# COMPUTE_CLUSTER0_A72SS0_COMMON_ECC_AGGR_MPU0_COREPAC_ECC_AGGR register map
Vendor: Texas Instruments
Peripheral module from a debugger description file (folder J721S2).
Registers are 32-bit, access not given, reset 0x0 unless marked. A register's access mark holds for its fields unless they carry their own. Offsets are as the file gives them; lines under a group give offsets from that group; [hi:lo] are bit positions; {n}, {i} and the like mark numbered series; 'fields as' and 'values as' point back to an identical list; <NAME> marks a mode.

## COMPUTE_CLUSTER0_A72SS0_COMMON_ECC_AGGR_MPU0_COREPAC_ECC_AGGR
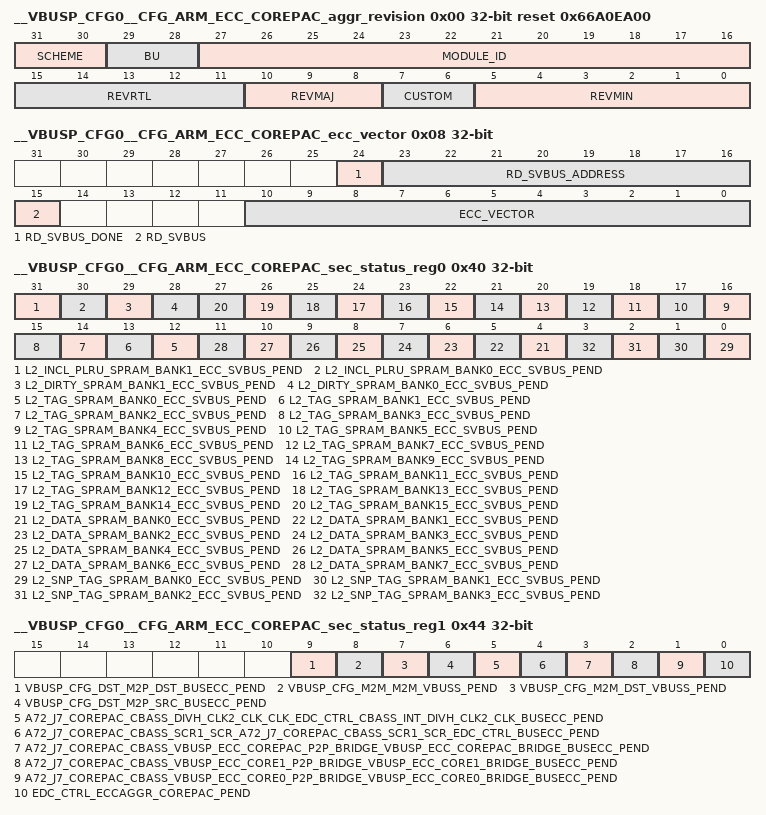
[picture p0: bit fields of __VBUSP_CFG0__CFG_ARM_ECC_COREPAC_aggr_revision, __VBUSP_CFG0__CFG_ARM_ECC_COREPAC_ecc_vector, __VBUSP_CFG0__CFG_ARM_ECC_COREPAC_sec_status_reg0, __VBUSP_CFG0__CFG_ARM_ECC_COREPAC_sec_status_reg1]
0x00 __VBUSP_CFG0__CFG_ARM_ECC_COREPAC_aggr_revision ro reset 0x66A0EA00 — Revision parameters
  [31:30] SCHEME
  [29:28] BU
  [27:16] MODULE_ID
  [15:11] REVRTL — RTL version
  [10:8] REVMAJ — Major version
  [7:6] CUSTOM — Custom version
  [5:0] REVMIN — Minor version
0x08 __VBUSP_CFG0__CFG_ARM_ECC_COREPAC_ecc_vector — ECC Vector Register
  [24] RD_SVBUS_DONE — Status to indicate if read on serial VBUS is complete, write of any value will clear this bit. (access R/W1TC)
  [23:16] RD_SVBUS_ADDRESS rw — Read address
  [15] RD_SVBUS — Write 1 to trigger a read on the serial VBUS (access R/W1TS)
  [10:0] ECC_VECTOR rw — Value written to select the corresponding ECC RAM for control or status
0x0C __VBUSP_CFG0__CFG_ARM_ECC_COREPAC_misc_status ro reset 0x2A — Misc Status
  [10:0] NUM_RAMS — Indicates the number of RAMS serviced by the ECC aggregator
0x10 __VBUSP_CFG0__CFG_ARM_ECC_COREPAC_reserved_svbus rw — Reference other documents that contain the ECC RAM wrapper and EDC controller serial vbus register sets.
  [31:0] DATA — Serial VBUS register data
0x3C __VBUSP_CFG0__CFG_ARM_ECC_COREPAC_sec_eoi_reg — EOI Register
  [0] EOI_WR — EOI Register (access R/W1TS)
0x40 __VBUSP_CFG0__CFG_ARM_ECC_COREPAC_sec_status_reg0 — Interrupt Status Register 0
  [31] L2_INCL_PLRU_SPRAM_BANK1_ECC_SVBUS_PEND — Interrupt Pending Status for l2_incl_plru_spram_bank1_ecc_svbus_pend (access R/W1TS)
  [30] L2_INCL_PLRU_SPRAM_BANK0_ECC_SVBUS_PEND — Interrupt Pending Status for l2_incl_plru_spram_bank0_ecc_svbus_pend (access R/W1TS)
  [29] L2_DIRTY_SPRAM_BANK1_ECC_SVBUS_PEND — Interrupt Pending Status for l2_dirty_spram_bank1_ecc_svbus_pend (access R/W1TS)
  [28] L2_DIRTY_SPRAM_BANK0_ECC_SVBUS_PEND — Interrupt Pending Status for l2_dirty_spram_bank0_ecc_svbus_pend (access R/W1TS)
  [n+12] L2_TAG_SPRAM_BANK{n}_ECC_SVBUS_PEND (n=0..15) — Interrupt Pending Status for l2_tag_spram_bank{n}_ecc_svbus_pend (access R/W1TS)
  [n+4] L2_DATA_SPRAM_BANK{n}_ECC_SVBUS_PEND (n=0..7) — Interrupt Pending Status for l2_data_spram_bank{n}_ecc_svbus_pend (access R/W1TS)
  [n] L2_SNP_TAG_SPRAM_BANK{n}_ECC_SVBUS_PEND (n=0..3) — Interrupt Pending Status for l2_snp_tag_spram_bank{n}_ecc_svbus_pend (access R/W1TS)
0x44 __VBUSP_CFG0__CFG_ARM_ECC_COREPAC_sec_status_reg1 — Interrupt Status Register 1
  [9] VBUSP_CFG_DST_M2P_DST_BUSECC_PEND — Interrupt Pending Status for vbusp_cfg_dst_m2p_dst_busecc_pend (access R/W1TS)
  [8] VBUSP_CFG_M2M_M2M_VBUSS_PEND — Interrupt Pending Status for vbusp_cfg_m2m_m2m_vbuss_pend (access R/W1TS)
  [7] VBUSP_CFG_M2M_DST_VBUSS_PEND — Interrupt Pending Status for vbusp_cfg_m2m_dst_vbuss_pend (access R/W1TS)
  [6] VBUSP_CFG_DST_M2P_SRC_BUSECC_PEND — Interrupt Pending Status for vbusp_cfg_dst_m2p_src_busecc_pend (access R/W1TS)
  [5] A72_J7_COREPAC_CBASS_DIVH_CLK2_CLK_CLK_EDC_CTRL_CBASS_INT_DIVH_CLK2_CLK_BUSECC_PEND — Interrupt Pending Status for a72_j7_corepac_cbass_divh_clk2_clk_clk_edc_ctrl_cbass_int_divh_clk2_clk_busecc_pend (access R/W1TS)
  [4] A72_J7_COREPAC_CBASS_SCR1_SCR_A72_J7_COREPAC_CBASS_SCR1_SCR_EDC_CTRL_BUSECC_PEND — Interrupt Pending Status for a72_j7_corepac_cbass_scr1_scr_a72_j7_corepac_cbass_scr1_scr_edc_ctrl_busecc_pend (access R/W1TS)
  [3] A72_J7_COREPAC_CBASS_VBUSP_ECC_COREPAC_P2P_BRIDGE_VBUSP_ECC_COREPAC_BRIDGE_BUSECC_PEND — Interrupt Pending Status for a72_j7_corepac_cbass_vbusp_ecc_corepac_p2p_bridge_vbusp_ecc_corepac_bridge_busecc_pend (access R/W1TS)
  [2] A72_J7_COREPAC_CBASS_VBUSP_ECC_CORE1_P2P_BRIDGE_VBUSP_ECC_CORE1_BRIDGE_BUSECC_PEND — Interrupt Pending Status for a72_j7_corepac_cbass_vbusp_ecc_core1_p2p_bridge_vbusp_ecc_core1_bridge_busecc_pend (access R/W1TS)
  [1] A72_J7_COREPAC_CBASS_VBUSP_ECC_CORE0_P2P_BRIDGE_VBUSP_ECC_CORE0_BRIDGE_BUSECC_PEND — Interrupt Pending Status for a72_j7_corepac_cbass_vbusp_ecc_core0_p2p_bridge_vbusp_ecc_core0_bridge_busecc_pend (access R/W1TS)
  [0] EDC_CTRL_ECCAGGR_COREPAC_PEND — Interrupt Pending Status for edc_ctrl_eccaggr_corepac_pend (access R/W1TS)
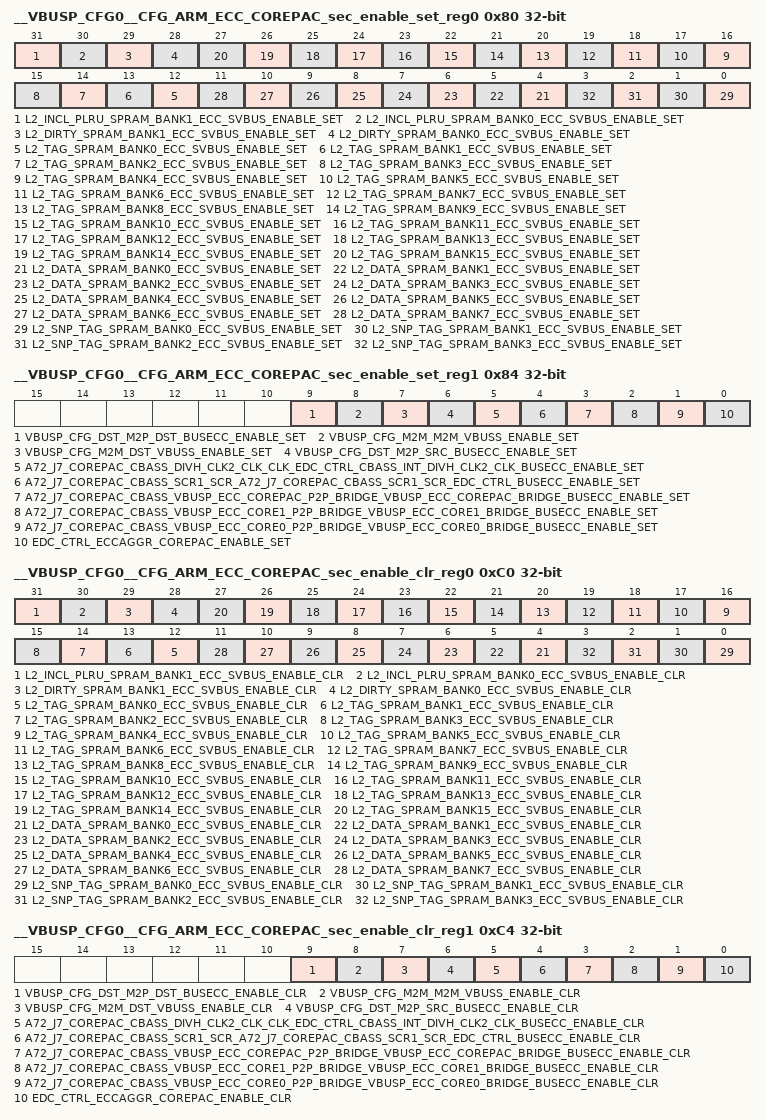
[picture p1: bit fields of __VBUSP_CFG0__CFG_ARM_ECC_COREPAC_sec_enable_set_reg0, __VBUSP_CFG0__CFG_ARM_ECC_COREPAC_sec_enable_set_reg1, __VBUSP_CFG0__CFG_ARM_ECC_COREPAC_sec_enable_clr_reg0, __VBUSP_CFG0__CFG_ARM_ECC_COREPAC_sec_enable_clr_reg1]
0x80 __VBUSP_CFG0__CFG_ARM_ECC_COREPAC_sec_enable_set_reg0 — Interrupt Enable Set Register 0
  [31] L2_INCL_PLRU_SPRAM_BANK1_ECC_SVBUS_ENABLE_SET — Interrupt Enable Set Register for l2_incl_plru_spram_bank1_ecc_svbus_pend (access R/W1TS)
  [30] L2_INCL_PLRU_SPRAM_BANK0_ECC_SVBUS_ENABLE_SET — Interrupt Enable Set Register for l2_incl_plru_spram_bank0_ecc_svbus_pend (access R/W1TS)
  [29] L2_DIRTY_SPRAM_BANK1_ECC_SVBUS_ENABLE_SET — Interrupt Enable Set Register for l2_dirty_spram_bank1_ecc_svbus_pend (access R/W1TS)
  [28] L2_DIRTY_SPRAM_BANK0_ECC_SVBUS_ENABLE_SET — Interrupt Enable Set Register for l2_dirty_spram_bank0_ecc_svbus_pend (access R/W1TS)
  [n+12] L2_TAG_SPRAM_BANK{n}_ECC_SVBUS_ENABLE_SET (n=0..15) — Interrupt Enable Set Register for l2_tag_spram_bank{n}_ecc_svbus_pend (access R/W1TS)
  [n+4] L2_DATA_SPRAM_BANK{n}_ECC_SVBUS_ENABLE_SET (n=0..7) — Interrupt Enable Set Register for l2_data_spram_bank{n}_ecc_svbus_pend (access R/W1TS)
  [n] L2_SNP_TAG_SPRAM_BANK{n}_ECC_SVBUS_ENABLE_SET (n=0..3) — Interrupt Enable Set Register for l2_snp_tag_spram_bank{n}_ecc_svbus_pend (access R/W1TS)
0x84 __VBUSP_CFG0__CFG_ARM_ECC_COREPAC_sec_enable_set_reg1 — Interrupt Enable Set Register 1
  [9] VBUSP_CFG_DST_M2P_DST_BUSECC_ENABLE_SET — Interrupt Enable Set Register for vbusp_cfg_dst_m2p_dst_busecc_pend (access R/W1TS)
  [8] VBUSP_CFG_M2M_M2M_VBUSS_ENABLE_SET — Interrupt Enable Set Register for vbusp_cfg_m2m_m2m_vbuss_pend (access R/W1TS)
  [7] VBUSP_CFG_M2M_DST_VBUSS_ENABLE_SET — Interrupt Enable Set Register for vbusp_cfg_m2m_dst_vbuss_pend (access R/W1TS)
  [6] VBUSP_CFG_DST_M2P_SRC_BUSECC_ENABLE_SET — Interrupt Enable Set Register for vbusp_cfg_dst_m2p_src_busecc_pend (access R/W1TS)
  [5] A72_J7_COREPAC_CBASS_DIVH_CLK2_CLK_CLK_EDC_CTRL_CBASS_INT_DIVH_CLK2_CLK_BUSECC_ENABLE_SET — Interrupt Enable Set Register for a72_j7_corepac_cbass_divh_clk2_clk_clk_edc_ctrl_cbass_int_divh_clk2_clk_busecc_pend (access R/W1TS)
  [4] A72_J7_COREPAC_CBASS_SCR1_SCR_A72_J7_COREPAC_CBASS_SCR1_SCR_EDC_CTRL_BUSECC_ENABLE_SET — Interrupt Enable Set Register for a72_j7_corepac_cbass_scr1_scr_a72_j7_corepac_cbass_scr1_scr_edc_ctrl_busecc_pend (access R/W1TS)
  [3] A72_J7_COREPAC_CBASS_VBUSP_ECC_COREPAC_P2P_BRIDGE_VBUSP_ECC_COREPAC_BRIDGE_BUSECC_ENABLE_SET — Interrupt Enable Set Register for a72_j7_corepac_cbass_vbusp_ecc_corepac_p2p_bridge_vbusp_ecc_corepac_bridge_busecc_pend (access R/W1TS)
  [2] A72_J7_COREPAC_CBASS_VBUSP_ECC_CORE1_P2P_BRIDGE_VBUSP_ECC_CORE1_BRIDGE_BUSECC_ENABLE_SET — Interrupt Enable Set Register for a72_j7_corepac_cbass_vbusp_ecc_core1_p2p_bridge_vbusp_ecc_core1_bridge_busecc_pend (access R/W1TS)
  [1] A72_J7_COREPAC_CBASS_VBUSP_ECC_CORE0_P2P_BRIDGE_VBUSP_ECC_CORE0_BRIDGE_BUSECC_ENABLE_SET — Interrupt Enable Set Register for a72_j7_corepac_cbass_vbusp_ecc_core0_p2p_bridge_vbusp_ecc_core0_bridge_busecc_pend (access R/W1TS)
  [0] EDC_CTRL_ECCAGGR_COREPAC_ENABLE_SET — Interrupt Enable Set Register for edc_ctrl_eccaggr_corepac_pend (access R/W1TS)
0xC0 __VBUSP_CFG0__CFG_ARM_ECC_COREPAC_sec_enable_clr_reg0 — Interrupt Enable Clear Register 0
  [31] L2_INCL_PLRU_SPRAM_BANK1_ECC_SVBUS_ENABLE_CLR — Interrupt Enable Clear Register for l2_incl_plru_spram_bank1_ecc_svbus_pend (access R/W1TC)
  [30] L2_INCL_PLRU_SPRAM_BANK0_ECC_SVBUS_ENABLE_CLR — Interrupt Enable Clear Register for l2_incl_plru_spram_bank0_ecc_svbus_pend (access R/W1TC)
  [29] L2_DIRTY_SPRAM_BANK1_ECC_SVBUS_ENABLE_CLR — Interrupt Enable Clear Register for l2_dirty_spram_bank1_ecc_svbus_pend (access R/W1TC)
  [28] L2_DIRTY_SPRAM_BANK0_ECC_SVBUS_ENABLE_CLR — Interrupt Enable Clear Register for l2_dirty_spram_bank0_ecc_svbus_pend (access R/W1TC)
  [n+12] L2_TAG_SPRAM_BANK{n}_ECC_SVBUS_ENABLE_CLR (n=0..15) — Interrupt Enable Clear Register for l2_tag_spram_bank{n}_ecc_svbus_pend (access R/W1TC)
  [n+4] L2_DATA_SPRAM_BANK{n}_ECC_SVBUS_ENABLE_CLR (n=0..7) — Interrupt Enable Clear Register for l2_data_spram_bank{n}_ecc_svbus_pend (access R/W1TC)
  [n] L2_SNP_TAG_SPRAM_BANK{n}_ECC_SVBUS_ENABLE_CLR (n=0..3) — Interrupt Enable Clear Register for l2_snp_tag_spram_bank{n}_ecc_svbus_pend (access R/W1TC)
0xC4 __VBUSP_CFG0__CFG_ARM_ECC_COREPAC_sec_enable_clr_reg1 — Interrupt Enable Clear Register 1
  [9] VBUSP_CFG_DST_M2P_DST_BUSECC_ENABLE_CLR — Interrupt Enable Clear Register for vbusp_cfg_dst_m2p_dst_busecc_pend (access R/W1TC)
  [8] VBUSP_CFG_M2M_M2M_VBUSS_ENABLE_CLR — Interrupt Enable Clear Register for vbusp_cfg_m2m_m2m_vbuss_pend (access R/W1TC)
  [7] VBUSP_CFG_M2M_DST_VBUSS_ENABLE_CLR — Interrupt Enable Clear Register for vbusp_cfg_m2m_dst_vbuss_pend (access R/W1TC)
  [6] VBUSP_CFG_DST_M2P_SRC_BUSECC_ENABLE_CLR — Interrupt Enable Clear Register for vbusp_cfg_dst_m2p_src_busecc_pend (access R/W1TC)
  [5] A72_J7_COREPAC_CBASS_DIVH_CLK2_CLK_CLK_EDC_CTRL_CBASS_INT_DIVH_CLK2_CLK_BUSECC_ENABLE_CLR — Interrupt Enable Clear Register for a72_j7_corepac_cbass_divh_clk2_clk_clk_edc_ctrl_cbass_int_divh_clk2_clk_busecc_pend (access R/W1TC)
  [4] A72_J7_COREPAC_CBASS_SCR1_SCR_A72_J7_COREPAC_CBASS_SCR1_SCR_EDC_CTRL_BUSECC_ENABLE_CLR — Interrupt Enable Clear Register for a72_j7_corepac_cbass_scr1_scr_a72_j7_corepac_cbass_scr1_scr_edc_ctrl_busecc_pend (access R/W1TC)
  [3] A72_J7_COREPAC_CBASS_VBUSP_ECC_COREPAC_P2P_BRIDGE_VBUSP_ECC_COREPAC_BRIDGE_BUSECC_ENABLE_CLR — Interrupt Enable Clear Register for a72_j7_corepac_cbass_vbusp_ecc_corepac_p2p_bridge_vbusp_ecc_corepac_bridge_busecc_pend (access R/W1TC)
  [2] A72_J7_COREPAC_CBASS_VBUSP_ECC_CORE1_P2P_BRIDGE_VBUSP_ECC_CORE1_BRIDGE_BUSECC_ENABLE_CLR — Interrupt Enable Clear Register for a72_j7_corepac_cbass_vbusp_ecc_core1_p2p_bridge_vbusp_ecc_core1_bridge_busecc_pend (access R/W1TC)
  [1] A72_J7_COREPAC_CBASS_VBUSP_ECC_CORE0_P2P_BRIDGE_VBUSP_ECC_CORE0_BRIDGE_BUSECC_ENABLE_CLR — Interrupt Enable Clear Register for a72_j7_corepac_cbass_vbusp_ecc_core0_p2p_bridge_vbusp_ecc_core0_bridge_busecc_pend (access R/W1TC)
  [0] EDC_CTRL_ECCAGGR_COREPAC_ENABLE_CLR — Interrupt Enable Clear Register for edc_ctrl_eccaggr_corepac_pend (access R/W1TC)
0x13C __VBUSP_CFG0__CFG_ARM_ECC_COREPAC_ded_eoi_reg — EOI Register
  [0] EOI_WR — EOI Register (access R/W1TS)
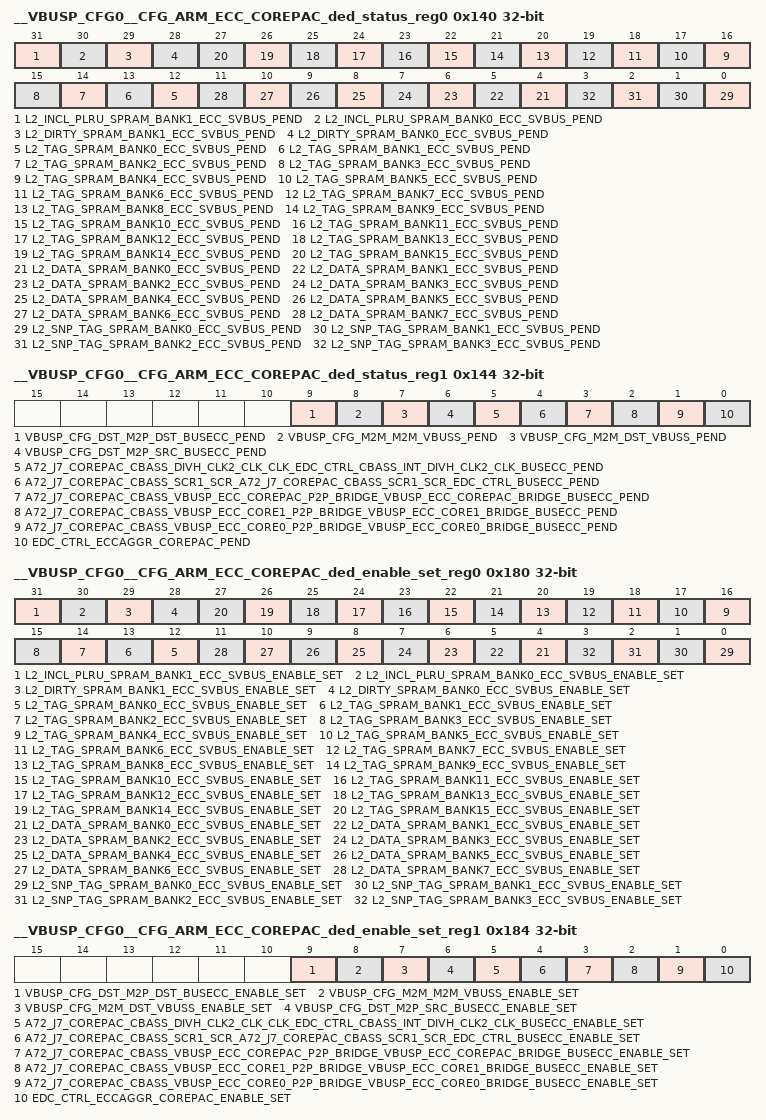
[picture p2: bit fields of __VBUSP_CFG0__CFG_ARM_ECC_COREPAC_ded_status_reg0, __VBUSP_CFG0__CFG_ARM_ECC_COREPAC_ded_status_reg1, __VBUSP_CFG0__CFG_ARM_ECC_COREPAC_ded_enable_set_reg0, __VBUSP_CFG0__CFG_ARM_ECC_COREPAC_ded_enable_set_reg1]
0x140 __VBUSP_CFG0__CFG_ARM_ECC_COREPAC_ded_status_reg0 — Interrupt Status Register 0
  fields as __VBUSP_CFG0__CFG_ARM_ECC_COREPAC_sec_status_reg0
0x144 __VBUSP_CFG0__CFG_ARM_ECC_COREPAC_ded_status_reg1 — Interrupt Status Register 1
  fields as __VBUSP_CFG0__CFG_ARM_ECC_COREPAC_sec_status_reg1
0x180 __VBUSP_CFG0__CFG_ARM_ECC_COREPAC_ded_enable_set_reg0 — Interrupt Enable Set Register 0
  fields as __VBUSP_CFG0__CFG_ARM_ECC_COREPAC_sec_enable_set_reg0
0x184 __VBUSP_CFG0__CFG_ARM_ECC_COREPAC_ded_enable_set_reg1 — Interrupt Enable Set Register 1
  fields as __VBUSP_CFG0__CFG_ARM_ECC_COREPAC_sec_enable_set_reg1
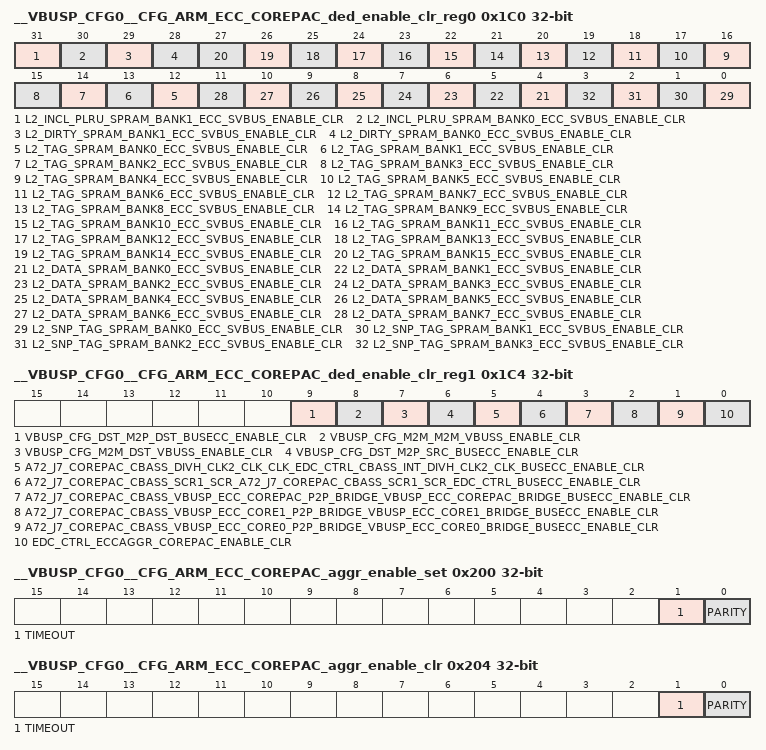
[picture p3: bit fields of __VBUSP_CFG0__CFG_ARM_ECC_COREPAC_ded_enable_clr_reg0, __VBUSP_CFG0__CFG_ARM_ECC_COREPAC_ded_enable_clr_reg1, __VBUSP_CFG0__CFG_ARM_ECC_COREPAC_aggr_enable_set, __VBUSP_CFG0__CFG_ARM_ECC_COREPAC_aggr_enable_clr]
0x1C0 __VBUSP_CFG0__CFG_ARM_ECC_COREPAC_ded_enable_clr_reg0 — Interrupt Enable Clear Register 0
  fields as __VBUSP_CFG0__CFG_ARM_ECC_COREPAC_sec_enable_clr_reg0
0x1C4 __VBUSP_CFG0__CFG_ARM_ECC_COREPAC_ded_enable_clr_reg1 — Interrupt Enable Clear Register 1
  fields as __VBUSP_CFG0__CFG_ARM_ECC_COREPAC_sec_enable_clr_reg1
0x200 __VBUSP_CFG0__CFG_ARM_ECC_COREPAC_aggr_enable_set — AGGR interrupt enable set Register
  [1] TIMEOUT — interrupt enable set for svbus timeout errors (access R/W1TS)
  [0] PARITY — interrupt enable set for parity errors (access R/W1TS)
0x204 __VBUSP_CFG0__CFG_ARM_ECC_COREPAC_aggr_enable_clr — AGGR interrupt enable clear Register
  [1] TIMEOUT — interrupt enable clear for svbus timeout errors (access R/W1TC)
  [0] PARITY — interrupt enable clear for parity errors (access R/W1TC)
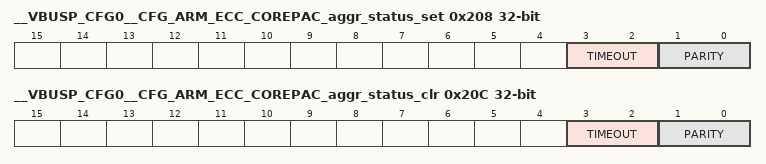
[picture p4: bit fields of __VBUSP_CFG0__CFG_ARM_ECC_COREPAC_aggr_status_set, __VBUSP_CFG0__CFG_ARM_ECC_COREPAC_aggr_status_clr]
0x208 __VBUSP_CFG0__CFG_ARM_ECC_COREPAC_aggr_status_set — AGGR interrupt status set Register
  [3:2] TIMEOUT — interrupt status set for svbus timeout errors (access R/WI)
  [1:0] PARITY — interrupt status set for parity errors (access R/WI)
0x20C __VBUSP_CFG0__CFG_ARM_ECC_COREPAC_aggr_status_clr — AGGR interrupt status clear Register
  [3:2] TIMEOUT — interrupt status clear for svbus timeout errors (access R/WD)
  [1:0] PARITY — interrupt status clear for parity errors (access R/WD)
